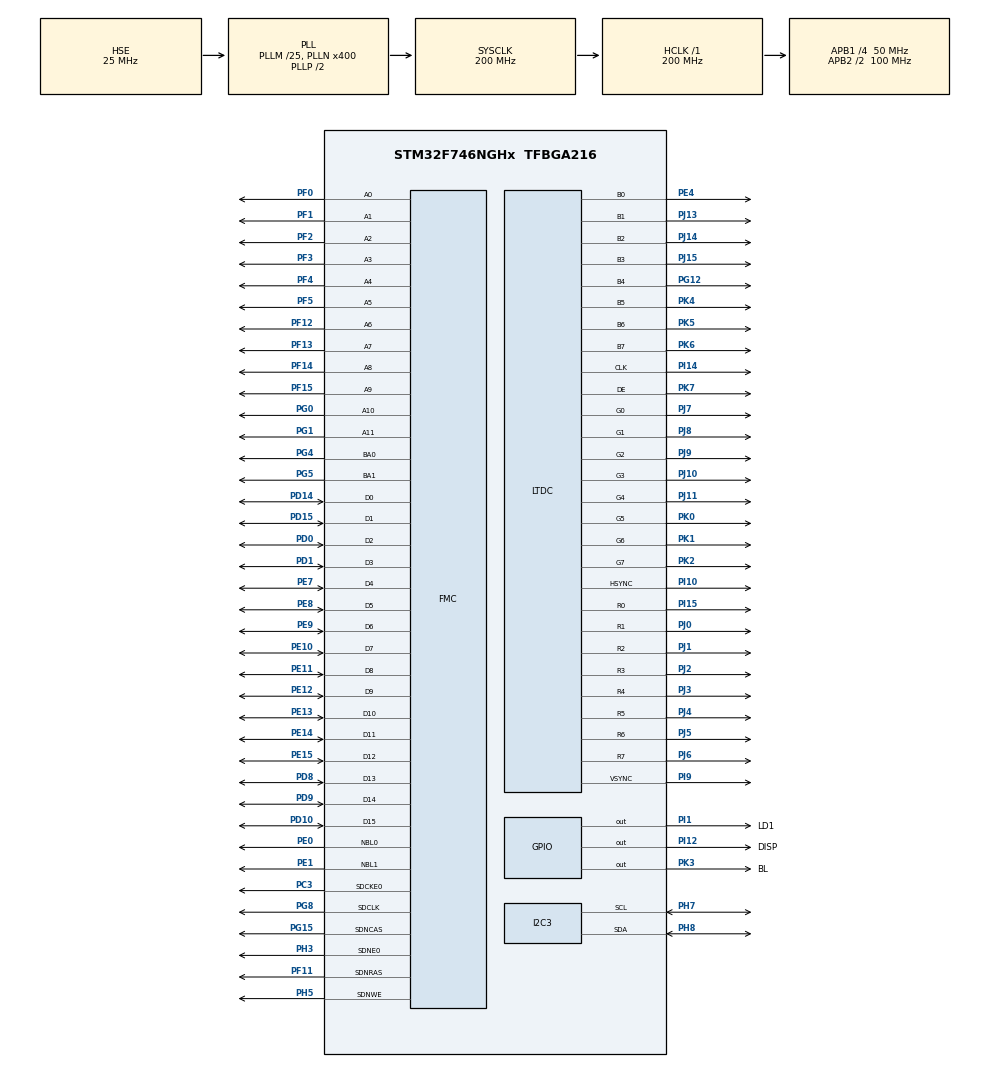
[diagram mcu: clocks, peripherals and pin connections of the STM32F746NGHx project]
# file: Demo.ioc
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FMC.CASLatency1=FMC_SDRAM_CAS_LATENCY_3
FMC.ExitSelfRefreshDelay1=7
FMC.LoadToActiveDelay1=2
FMC.RCDDelay1=2
FMC.RPDelay1=2
FMC.ReadBurst1=FMC_SDRAM_RBURST_ENABLE
FMC.RowCycleDelay1=7
FMC.SDClockPeriod1=FMC_SDRAM_CLOCK_PERIOD_2
FMC.SelfRefreshTime1=4
FMC.WriteRecoveryTime1=3
I2C3.Timing=0x00C0EAFF
LTDC.ActiveH=272
LTDC.ActiveW=480
LTDC.Alpha_L0=255
LTDC.BlendingFactor1_L0=LTDC_BLENDING_FACTOR1_PAxCA
LTDC.BlendingFactor2_L0=LTDC_BLENDING_FACTOR2_PAxCA
LTDC.FBStartAdress_L0=0xC0000000
LTDC.HBP=RK043FN48H_HBP
LTDC.HFP=RK043FN48H_HFP
LTDC.HSync=RK043FN48H_HSYNC
LTDC.ImageHeight_L0=272
LTDC.ImageWidth_L0=480
LTDC.Layers=0
LTDC.PixelFormat_L0=LTDC_PIXEL_FORMAT_RGB565
LTDC.VBP=RK043FN48H_VBP
LTDC.VFP=RK043FN48H_VFP
LTDC.VSync=RK043FN48H_VSYNC
LTDC.WindowX1_L0=480
LTDC.WindowY1_L0=272
Mcu.Family=STM32F7
Mcu.Name=STM32F746NGHx
Mcu.Package=TFBGA216
Mcu.UserConstants=RK043FN48H_HSYNC,41;RK043FN48H_VSYNC,10;RK043FN48H_HBP,13;RK043FN48H_VBP,2;RK043FN48H_WIDHT,480;RK043FN48H_HEIGHT,272;RK043FN48H_HFP,32;RK043FN48H_VFP,2
NVIC.DMA2D_IRQn=true\:5\:0\:true\:false\:true\:true\:true
NVIC.FMC_IRQn=true\:5\:0\:true\:false\:true\:true\:true
NVIC.LTDC_IRQn=true\:5\:0\:true\:false\:true\:true\:true
NVIC.PriorityGroup=NVIC_PRIORITYGROUP_4
NVIC.RCC_IRQn=true\:0\:0\:false\:false\:true\:true\:false
NVIC.TIM6_DAC_IRQn=true\:0\:0\:false\:false\:true\:false\:true
NVIC.TimeBase=TIM6_DAC_IRQn
NVIC.TimeBaseIP=TIM6
PA13.Mode=Serial_Wire
PA13.Signal=SYS_JTMS-SWDIO
PA14.Mode=Serial_Wire
PA14.Signal=SYS_JTCK-SWCLK
PC14/OSC32_IN.Mode=LSE-External-Oscillator
PC14/OSC32_IN.Signal=RCC_OSC32_IN
PC15/OSC32_OUT.Mode=LSE-External-Oscillator
PC15/OSC32_OUT.Signal=RCC_OSC32_OUT
PC3.Mode=SdramChipSelect1_1
PC3.Signal=FMC_SDCKE0
PD0.Signal=FMC_D2_DA2
PD1.Signal=FMC_D3_DA3
PD10.Signal=FMC_D15_DA15
PD14.Signal=FMC_D0_DA0
PD15.Signal=FMC_D1_DA1
PD8.Signal=FMC_D13_DA13
PD9.Signal=FMC_D14_DA14
PE0.Signal=FMC_NBL0
PE1.Signal=FMC_NBL1
PE10.Signal=FMC_D7_DA7
PE11.Signal=FMC_D8_DA8
PE12.Signal=FMC_D9_DA9
PE13.Signal=FMC_D10_DA10
PE14.Signal=FMC_D11_DA11
PE15.Signal=FMC_D12_DA12
PE4.Mode=RGB888
PE4.Signal=LTDC_B0
PE7.Signal=FMC_D4_DA4
PE8.Signal=FMC_D5_DA5
PE9.Signal=FMC_D6_DA6
PF0.Signal=FMC_A0
PF1.Signal=FMC_A1
PF11.Signal=FMC_SDNRAS
PF12.Signal=FMC_A6
PF13.Signal=FMC_A7
PF14.Signal=FMC_A8
PF15.Signal=FMC_A9
PF2.Signal=FMC_A2
PF3.Signal=FMC_A3
PF4.Signal=FMC_A4
PF5.Signal=FMC_A5
PG0.Signal=FMC_A10
PG1.Signal=FMC_A11
PG12.Mode=RGB888
PG12.Signal=LTDC_B4
PG15.Signal=FMC_SDNCAS
PG4.Signal=FMC_A14_BA0
PG5.Signal=FMC_A15_BA1
PG8.Signal=FMC_SDCLK
PH0/OSC_IN.Mode=HSE-External-Clock-Source
PH0/OSC_IN.Signal=RCC_OSC_IN
PH1/OSC_OUT.Mode=HSE-External-Clock-Source
PH1/OSC_OUT.Signal=RCC_OSC_OUT
PH3.Mode=SdramChipSelect1_1
PH3.Signal=FMC_SDNE0
PH5.Signal=FMC_SDNWE
PH7.Mode=I2C
PH7.Signal=I2C3_SCL
PH8.Mode=I2C
PH8.Signal=I2C3_SDA
PI1.GPIO_Label=LD1
PI1.Signal=GPIO_Output
PI10.Mode=RGB888
PI10.Signal=LTDC_HSYNC
PI12.GPIO_Label=DISP
PI12.PinState=GPIO_PIN_SET
PI12.Signal=GPIO_Output
PI14.Mode=RGB888
PI14.Signal=LTDC_CLK
PI15.Mode=RGB888
PI15.Signal=LTDC_R0
PI9.Mode=RGB888
PI9.Signal=LTDC_VSYNC
PJ0.Mode=RGB888
PJ0.Signal=LTDC_R1
PJ1.Mode=RGB888
PJ1.Signal=LTDC_R2
PJ10.Mode=RGB888
PJ10.Signal=LTDC_G3
PJ11.Mode=RGB888
PJ11.Signal=LTDC_G4
PJ13.Mode=RGB888
PJ13.Signal=LTDC_B1
PJ14.Mode=RGB888
PJ14.Signal=LTDC_B2
PJ15.Mode=RGB888
PJ15.Signal=LTDC_B3
PJ2.Mode=RGB888
PJ2.Signal=LTDC_R3
PJ3.Mode=RGB888
PJ3.Signal=LTDC_R4
PJ4.Mode=RGB888
PJ4.Signal=LTDC_R5
PJ5.Mode=RGB888
PJ5.Signal=LTDC_R6
PJ6.Mode=RGB888
PJ6.Signal=LTDC_R7
PJ7.Mode=RGB888
PJ7.Signal=LTDC_G0
PJ8.Mode=RGB888
PJ8.Signal=LTDC_G1
PJ9.Mode=RGB888
PJ9.Signal=LTDC_G2
PK0.Mode=RGB888
PK0.Signal=LTDC_G5
PK1.Mode=RGB888
PK1.Signal=LTDC_G6
PK2.Mode=RGB888
PK2.Signal=LTDC_G7
PK3.GPIO_Label=BL
PK3.PinState=GPIO_PIN_SET
PK3.Signal=GPIO_Output
PK4.Mode=RGB888
PK4.Signal=LTDC_B5
PK5.Mode=RGB888
PK5.Signal=LTDC_B6
PK6.Mode=RGB888
PK6.Signal=LTDC_B7
PK7.Mode=RGB888
PK7.Signal=LTDC_DE
ProjectManager.HeapSize=0x200
ProjectManager.StackSize=0x400
ProjectManager.TargetToolchain=MDK-ARM V5.27
RCC.AHBFreq_Value=200000000
RCC.APB1CLKDivider=RCC_HCLK_DIV4
RCC.APB1Freq_Value=50000000
RCC.APB1TimFreq_Value=100000000
RCC.APB2CLKDivider=RCC_HCLK_DIV2
RCC.APB2Freq_Value=100000000
RCC.APB2TimFreq_Value=200000000
RCC.CortexFreq_Value=200000000
RCC.HCLKFreq_Value=200000000
RCC.HSE_VALUE=25000000
RCC.HSI_VALUE=16000000
RCC.PLLM=25
RCC.PLLN=400
RCC.PLLSAIN=384
RCC.PLLSAIR=5
RCC.PLLSAIRDiv=RCC_PLLSAIDIVR_8
RCC.PLLSourceVirtual=RCC_PLLSOURCE_HSE
RCC.SYSCLKFreq_VALUE=200000000
RCC.SYSCLKSource=RCC_SYSCLKSOURCE_PLLCLK
RCC.USBFreq_Value=200000000
RCC.VCOOutputFreq_Value=400000000
SH.FMC_A0.0=FMC_A0,12b-sda1
SH.FMC_A1.0=FMC_A1,12b-sda1
SH.FMC_A10.0=FMC_A10,12b-sda1
SH.FMC_A11.0=FMC_A11,12b-sda1
SH.FMC_A14_BA0.0=FMC_BA0,FourSdramBanks1
SH.FMC_A15_BA1.0=FMC_BA1,FourSdramBanks1
SH.FMC_A2.0=FMC_A2,12b-sda1
SH.FMC_A3.0=FMC_A3,12b-sda1
SH.FMC_A4.0=FMC_A4,12b-sda1
SH.FMC_A5.0=FMC_A5,12b-sda1
SH.FMC_A6.0=FMC_A6,12b-sda1
SH.FMC_A7.0=FMC_A7,12b-sda1
SH.FMC_A8.0=FMC_A8,12b-sda1
SH.FMC_A9.0=FMC_A9,12b-sda1
SH.FMC_D0_DA0.0=FMC_D0,sd-16b-d1
SH.FMC_D10_DA10.0=FMC_D10,sd-16b-d1
SH.FMC_D11_DA11.0=FMC_D11,sd-16b-d1
SH.FMC_D12_DA12.0=FMC_D12,sd-16b-d1
SH.FMC_D13_DA13.0=FMC_D13,sd-16b-d1
SH.FMC_D14_DA14.0=FMC_D14,sd-16b-d1
SH.FMC_D15_DA15.0=FMC_D15,sd-16b-d1
SH.FMC_D1_DA1.0=FMC_D1,sd-16b-d1
SH.FMC_D2_DA2.0=FMC_D2,sd-16b-d1
SH.FMC_D3_DA3.0=FMC_D3,sd-16b-d1
SH.FMC_D4_DA4.0=FMC_D4,sd-16b-d1
SH.FMC_D5_DA5.0=FMC_D5,sd-16b-d1
SH.FMC_D6_DA6.0=FMC_D6,sd-16b-d1
SH.FMC_D7_DA7.0=FMC_D7,sd-16b-d1
SH.FMC_D8_DA8.0=FMC_D8,sd-16b-d1
SH.FMC_D9_DA9.0=FMC_D9,sd-16b-d1
SH.FMC_NBL0.0=FMC_NBL0,Sd2ByteEnable1
SH.FMC_NBL1.0=FMC_NBL1,Sd2ByteEnable1
SH.FMC_SDCLK.0=FMC_SDCLK,12b-sda1
SH.FMC_SDNCAS.0=FMC_SDNCAS,12b-sda1
SH.FMC_SDNRAS.0=FMC_SDNRAS,12b-sda1
SH.FMC_SDNWE.0=FMC_SDNWE,12b-sda1
STMicroelectronics.X-CUBE-TOUCHGFX.4.13.0.ApplicationCcGraphicsJjApplication=TouchGFXOoGenerator
STMicroelectronics.X-CUBE-TOUCHGFX.4.13.0.tgfx_address1=0xC0000000
STMicroelectronics.X-CUBE-TOUCHGFX.4.13.0.tgfx_address2=0xC003fc00
STMicroelectronics.X-CUBE-TOUCHGFX.4.13.0.tgfx_buffering_strategy=Double
STMicroelectronics.X-CUBE-TOUCHGFX.4.13.0.tgfx_display_interface=disp_ltdc
STMicroelectronics.X-CUBE-TOUCHGFX.4.13.0.tgfx_hardware_accelerator=dma_2d
STMicroelectronics.X-CUBE-TOUCHGFX.4.13.0.tgfx_location=By Address
STMicroelectronics.X-CUBE-TOUCHGFX.4.13.0.tgfx_oswrapper=Custom
STMicroelectronics.X-CUBE-TOUCHGFX.4.13.0.tgfx_pixel_format=RGB565\:16
STMicroelectronics.X-CUBE-TOUCHGFX.4.13.0.tgfx_vsync=vsync_ltdc
VP_CRC_VS_CRC.Mode=CRC_Activate
VP_DMA2D_VS_DMA2D.Mode=DMA2D_Activate
VP_STMicroelectronics.X-CUBE-TOUCHGFX_VS_GraphicsJjApplication_4.13.0.Mode=GraphicsJjApplication
VP_SYS_VS_tim6.Mode=TIM6
board=custom

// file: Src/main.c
/* USER CODE BEGIN Header */
/**
  ******************************************************************************
  * @file           : main.c
  * @brief          : Main program body
  ******************************************************************************
  * @attention
  *
  * <h2><center>&copy; Copyright (c) 2020 STMicroelectronics.
  * All rights reserved.</center></h2>
  *
  * This software component is licensed by ST under Ultimate Liberty license
  * SLA0044, the "License"; You may not use this file except in compliance with
  * the License. You may obtain a copy of the License at:
  *                             www.st.com/SLA0044
  *
  ******************************************************************************
  */
/* USER CODE END Header */

#include "main.h"
#include "app_touchgfx.h"

/* USER CODE BEGIN Includes */
#include <rtthread.h>
/* USER CODE END Includes */

/* USER CODE BEGIN PD */
#define SDRAM_MODEREG_BURST_LENGTH_1             ((uint16_t)0x0000)
#define SDRAM_MODEREG_BURST_LENGTH_2             ((uint16_t)0x0001)
#define SDRAM_MODEREG_BURST_LENGTH_4             ((uint16_t)0x0002)
#define SDRAM_MODEREG_BURST_LENGTH_8             ((uint16_t)0x0004)
#define SDRAM_MODEREG_BURST_TYPE_SEQUENTIAL      ((uint16_t)0x0000)
#define SDRAM_MODEREG_BURST_TYPE_INTERLEAVED     ((uint16_t)0x0008)
#define SDRAM_MODEREG_CAS_LATENCY_2              ((uint16_t)0x0020)
#define SDRAM_MODEREG_CAS_LATENCY_3              ((uint16_t)0x0030)
#define SDRAM_MODEREG_OPERATING_MODE_STANDARD    ((uint16_t)0x0000)
#define SDRAM_MODEREG_WRITEBURST_MODE_PROGRAMMED ((uint16_t)0x0000)
#define SDRAM_MODEREG_WRITEBURST_MODE_SINGLE     ((uint16_t)0x0200)
/* USER CODE END PD */

CRC_HandleTypeDef hcrc;

DMA2D_HandleTypeDef hdma2d;

I2C_HandleTypeDef hi2c3;

LTDC_HandleTypeDef hltdc;

SDRAM_HandleTypeDef hsdram1;

void SystemClock_Config(void);
static void MX_GPIO_Init(void);
static void MX_CRC_Init(void);
static void MX_DMA2D_Init(void);
static void MX_FMC_Init(void);
static void MX_LTDC_Init(void);
static void MX_I2C3_Init(void);
/* USER CODE BEGIN PFP */
static void MX_SDRAM_Init(void);
/* USER CODE END PFP */

/* USER CODE BEGIN 0 */
static rt_thread_t tid = RT_NULL;
static void TouchGFX_entry(void *param)
{
    MX_TouchGFX_Process();
    for(;;)
    {
        rt_thread_delay(10);
    }
}
/* USER CODE END 0 */

int main(void)
{

    /* MCU Configuration--------------------------------------------------------*/

    /* Reset of all peripherals, Initializes the Flash interface and the Systick. */
    //HAL_Init();

    /* Configure the system clock */
    //SystemClock_Config();

    /* Initialize all configured peripherals */
    MX_GPIO_Init();
    MX_CRC_Init();
    MX_DMA2D_Init();
    MX_FMC_Init();
    MX_LTDC_Init();
    MX_I2C3_Init();
    MX_TouchGFX_Init();
    /* USER CODE BEGIN 2 */
    tid = rt_thread_create("TouchGFX", TouchGFX_entry, RT_NULL, 1024, 15, 20);
    if(tid != RT_NULL)
        rt_thread_startup(tid);
    /* USER CODE END 2 */

    /* Infinite loop */
    while (1)
    {

        //MX_TouchGFX_Process();
        /* USER CODE BEGIN 3 */
        HAL_GPIO_WritePin(LD1_GPIO_Port, LD1_Pin, GPIO_PIN_SET);
        rt_thread_delay(500);
        HAL_GPIO_WritePin(LD1_GPIO_Port, LD1_Pin, GPIO_PIN_RESET);
        rt_thread_delay(500);
    }
    /* USER CODE END 3 */
}

void SystemClock_Config(void)
{
    RCC_OscInitTypeDef RCC_OscInitStruct = {0};
    RCC_ClkInitTypeDef RCC_ClkInitStruct = {0};
    RCC_PeriphCLKInitTypeDef PeriphClkInitStruct = {0};

    /** Configure LSE Drive Capability
    */
    HAL_PWR_EnableBkUpAccess();
    /** Configure the main internal regulator output voltage
    */
    __HAL_RCC_PWR_CLK_ENABLE();
    __HAL_PWR_VOLTAGESCALING_CONFIG(PWR_REGULATOR_VOLTAGE_SCALE1);
    /** Initializes the CPU, AHB and APB busses clocks
    */
    RCC_OscInitStruct.OscillatorType = RCC_OSCILLATORTYPE_HSE;
    RCC_OscInitStruct.HSEState = RCC_HSE_BYPASS;
    RCC_OscInitStruct.PLL.PLLState = RCC_PLL_ON;
    RCC_OscInitStruct.PLL.PLLSource = RCC_PLLSOURCE_HSE;
    RCC_OscInitStruct.PLL.PLLM = 25;
    RCC_OscInitStruct.PLL.PLLN = 400;
    RCC_OscInitStruct.PLL.PLLP = RCC_PLLP_DIV2;
    RCC_OscInitStruct.PLL.PLLQ = 2;
    if (HAL_RCC_OscConfig(&RCC_OscInitStruct) != HAL_OK)
    {
        Error_Handler();
    }
    /** Activate the Over-Drive mode
    */
    if (HAL_PWREx_EnableOverDrive() != HAL_OK)
    {
        Error_Handler();
    }
    /** Initializes the CPU, AHB and APB busses clocks
    */
    RCC_ClkInitStruct.ClockType = RCC_CLOCKTYPE_HCLK | RCC_CLOCKTYPE_SYSCLK
                                  | RCC_CLOCKTYPE_PCLK1 | RCC_CLOCKTYPE_PCLK2;
    RCC_ClkInitStruct.SYSCLKSource = RCC_SYSCLKSOURCE_PLLCLK;
    RCC_ClkInitStruct.AHBCLKDivider = RCC_SYSCLK_DIV1;
    RCC_ClkInitStruct.APB1CLKDivider = RCC_HCLK_DIV4;
    RCC_ClkInitStruct.APB2CLKDivider = RCC_HCLK_DIV2;

    if (HAL_RCC_ClockConfig(&RCC_ClkInitStruct, FLASH_LATENCY_6) != HAL_OK)
    {
        Error_Handler();
    }
    PeriphClkInitStruct.PeriphClockSelection = RCC_PERIPHCLK_LTDC | RCC_PERIPHCLK_I2C3;
    PeriphClkInitStruct.PLLSAI.PLLSAIN = 384;
    PeriphClkInitStruct.PLLSAI.PLLSAIR = 5;
    PeriphClkInitStruct.PLLSAI.PLLSAIQ = 2;
    PeriphClkInitStruct.PLLSAI.PLLSAIP = RCC_PLLSAIP_DIV2;
    PeriphClkInitStruct.PLLSAIDivQ = 1;
    PeriphClkInitStruct.PLLSAIDivR = RCC_PLLSAIDIVR_8;
    PeriphClkInitStruct.I2c3ClockSelection = RCC_I2C3CLKSOURCE_PCLK1;
    if (HAL_RCCEx_PeriphCLKConfig(&PeriphClkInitStruct) != HAL_OK)
    {
        Error_Handler();
    }
}

static void MX_CRC_Init(void)
{

    hcrc.Instance = CRC;
    hcrc.Init.DefaultPolynomialUse = DEFAULT_POLYNOMIAL_ENABLE;
    hcrc.Init.DefaultInitValueUse = DEFAULT_INIT_VALUE_ENABLE;
    hcrc.Init.InputDataInversionMode = CRC_INPUTDATA_INVERSION_NONE;
    hcrc.Init.OutputDataInversionMode = CRC_OUTPUTDATA_INVERSION_DISABLE;
    hcrc.InputDataFormat = CRC_INPUTDATA_FORMAT_BYTES;
    if (HAL_CRC_Init(&hcrc) != HAL_OK)
    {
        Error_Handler();
    }

}

static void MX_DMA2D_Init(void)
{

    hdma2d.Instance = DMA2D;
    hdma2d.Init.Mode = DMA2D_M2M;
    hdma2d.Init.ColorMode = DMA2D_OUTPUT_ARGB8888;
    hdma2d.Init.OutputOffset = 0;
    hdma2d.LayerCfg[1].InputOffset = 0;
    hdma2d.LayerCfg[1].InputColorMode = DMA2D_INPUT_ARGB8888;
    hdma2d.LayerCfg[1].AlphaMode = DMA2D_NO_MODIF_ALPHA;
    hdma2d.LayerCfg[1].InputAlpha = 0;
    if (HAL_DMA2D_Init(&hdma2d) != HAL_OK)
    {
        Error_Handler();
    }
    if (HAL_DMA2D_ConfigLayer(&hdma2d, 1) != HAL_OK)
    {
        Error_Handler();
    }

}

static void MX_I2C3_Init(void)
{

    hi2c3.Instance = I2C3;
    hi2c3.Init.Timing = 0x00C0EAFF;
    hi2c3.Init.OwnAddress1 = 0;
    hi2c3.Init.AddressingMode = I2C_ADDRESSINGMODE_7BIT;
    hi2c3.Init.DualAddressMode = I2C_DUALADDRESS_DISABLE;
    hi2c3.Init.OwnAddress2 = 0;
    hi2c3.Init.OwnAddress2Masks = I2C_OA2_NOMASK;
    hi2c3.Init.GeneralCallMode = I2C_GENERALCALL_DISABLE;
    hi2c3.Init.NoStretchMode = I2C_NOSTRETCH_DISABLE;
    if (HAL_I2C_Init(&hi2c3) != HAL_OK)
    {
        Error_Handler();
    }
    /** Configure Analogue filter
    */
    if (HAL_I2CEx_ConfigAnalogFilter(&hi2c3, I2C_ANALOGFILTER_ENABLE) != HAL_OK)
    {
        Error_Handler();
    }
    /** Configure Digital filter
    */
    if (HAL_I2CEx_ConfigDigitalFilter(&hi2c3, 0) != HAL_OK)
    {
        Error_Handler();
    }

}

static void MX_LTDC_Init(void)
{

    LTDC_LayerCfgTypeDef pLayerCfg = {0};

    hltdc.Instance = LTDC;
    hltdc.Init.HSPolarity = LTDC_HSPOLARITY_AL;
    hltdc.Init.VSPolarity = LTDC_VSPOLARITY_AL;
    hltdc.Init.DEPolarity = LTDC_DEPOLARITY_AL;
    hltdc.Init.PCPolarity = LTDC_PCPOLARITY_IPC;
    hltdc.Init.HorizontalSync = 40;
    hltdc.Init.VerticalSync = 9;
    hltdc.Init.AccumulatedHBP = 53;
    hltdc.Init.AccumulatedVBP = 11;
    hltdc.Init.AccumulatedActiveW = 533;
    hltdc.Init.AccumulatedActiveH = 283;
    hltdc.Init.TotalWidth = 565;
    hltdc.Init.TotalHeigh = 285;
    hltdc.Init.Backcolor.Blue = 0;
    hltdc.Init.Backcolor.Green = 0;
    hltdc.Init.Backcolor.Red = 0;
    if (HAL_LTDC_Init(&hltdc) != HAL_OK)
    {
        Error_Handler();
    }
    pLayerCfg.WindowX0 = 0;
    pLayerCfg.WindowX1 = 480;
    pLayerCfg.WindowY0 = 0;
    pLayerCfg.WindowY1 = 272;
    pLayerCfg.PixelFormat = LTDC_PIXEL_FORMAT_RGB565;
    pLayerCfg.Alpha = 255;
    pLayerCfg.Alpha0 = 0;
    pLayerCfg.BlendingFactor1 = LTDC_BLENDING_FACTOR1_PAxCA;
    pLayerCfg.BlendingFactor2 = LTDC_BLENDING_FACTOR2_PAxCA;
    pLayerCfg.FBStartAdress = 0xC0000000;
    pLayerCfg.ImageWidth = 480;
    pLayerCfg.ImageHeight = 272;
    pLayerCfg.Backcolor.Blue = 0;
    pLayerCfg.Backcolor.Green = 0;
    pLayerCfg.Backcolor.Red = 0;
    if (HAL_LTDC_ConfigLayer(&hltdc, &pLayerCfg, 0) != HAL_OK)
    {
        Error_Handler();
    }

}

/* FMC initialization function */
static void MX_FMC_Init(void)
{

    FMC_SDRAM_TimingTypeDef SdramTiming = {0};

    /** Perform the SDRAM1 memory initialization sequence
    */
    hsdram1.Instance = FMC_SDRAM_DEVICE;
    /* hsdram1.Init */
    hsdram1.Init.SDBank = FMC_SDRAM_BANK1;
    hsdram1.Init.ColumnBitsNumber = FMC_SDRAM_COLUMN_BITS_NUM_8;
    hsdram1.Init.RowBitsNumber = FMC_SDRAM_ROW_BITS_NUM_12;
    hsdram1.Init.MemoryDataWidth = FMC_SDRAM_MEM_BUS_WIDTH_16;
    hsdram1.Init.InternalBankNumber = FMC_SDRAM_INTERN_BANKS_NUM_4;
    hsdram1.Init.CASLatency = FMC_SDRAM_CAS_LATENCY_3;
    hsdram1.Init.WriteProtection = FMC_SDRAM_WRITE_PROTECTION_DISABLE;
    hsdram1.Init.SDClockPeriod = FMC_SDRAM_CLOCK_PERIOD_2;
    hsdram1.Init.ReadBurst = FMC_SDRAM_RBURST_ENABLE;
    hsdram1.Init.ReadPipeDelay = FMC_SDRAM_RPIPE_DELAY_0;
    /* SdramTiming */
    SdramTiming.LoadToActiveDelay = 2;
    SdramTiming.ExitSelfRefreshDelay = 7;
    SdramTiming.SelfRefreshTime = 4;
    SdramTiming.RowCycleDelay = 7;
    SdramTiming.WriteRecoveryTime = 3;
    SdramTiming.RPDelay = 2;
    SdramTiming.RCDDelay = 2;

    if (HAL_SDRAM_Init(&hsdram1, &SdramTiming) != HAL_OK)
    {
        Error_Handler( );
    }

    /* USER CODE BEGIN FMC_Init 2 */
    MX_SDRAM_Init();
    /* USER CODE END FMC_Init 2 */
}

static void MX_GPIO_Init(void)
{
    GPIO_InitTypeDef GPIO_InitStruct = {0};

    /* GPIO Ports Clock Enable */
    __HAL_RCC_GPIOE_CLK_ENABLE();
    __HAL_RCC_GPIOA_CLK_ENABLE();
    __HAL_RCC_GPIOG_CLK_ENABLE();
    __HAL_RCC_GPIOJ_CLK_ENABLE();
    __HAL_RCC_GPIOD_CLK_ENABLE();
    __HAL_RCC_GPIOK_CLK_ENABLE();
    __HAL_RCC_GPIOF_CLK_ENABLE();
    __HAL_RCC_GPIOI_CLK_ENABLE();
    __HAL_RCC_GPIOC_CLK_ENABLE();
    __HAL_RCC_GPIOH_CLK_ENABLE();

    /*Configure GPIO pin Output Level */
    HAL_GPIO_WritePin(BL_GPIO_Port, BL_Pin, GPIO_PIN_SET);

    /*Configure GPIO pin Output Level */
    HAL_GPIO_WritePin(LD1_GPIO_Port, LD1_Pin, GPIO_PIN_RESET);

    /*Configure GPIO pin Output Level */
    HAL_GPIO_WritePin(DISP_GPIO_Port, DISP_Pin, GPIO_PIN_SET);

    /*Configure GPIO pin : BL_Pin */
    GPIO_InitStruct.Pin = BL_Pin;
    GPIO_InitStruct.Mode = GPIO_MODE_OUTPUT_PP;
    GPIO_InitStruct.Pull = GPIO_NOPULL;
    GPIO_InitStruct.Speed = GPIO_SPEED_FREQ_LOW;
    HAL_GPIO_Init(BL_GPIO_Port, &GPIO_InitStruct);

    /*Configure GPIO pins : LD1_Pin DISP_Pin */
    GPIO_InitStruct.Pin = LD1_Pin | DISP_Pin;
    GPIO_InitStruct.Mode = GPIO_MODE_OUTPUT_PP;
    GPIO_InitStruct.Pull = GPIO_NOPULL;
    GPIO_InitStruct.Speed = GPIO_SPEED_FREQ_LOW;
    HAL_GPIO_Init(GPIOI, &GPIO_InitStruct);

}

/* USER CODE BEGIN 4 */

/**
  * @brief SDRAM Initialization Function
  * @param None
  * @retval None
  */
static void MX_SDRAM_Init(void)
{
    __IO uint32_t tmpmrd = 0;

    FMC_SDRAM_CommandTypeDef Command;

    /* Step 1: Config clock */
    Command.CommandMode             = FMC_SDRAM_CMD_CLK_ENABLE;
    Command.CommandTarget           = FMC_SDRAM_CMD_TARGET_BANK1;
    Command.AutoRefreshNumber       = 1;
    Command.ModeRegisterDefinition  = 0;
    HAL_SDRAM_SendCommand(&hsdram1, &Command, 0xFFFF);

    /* Step 2: Insert Delay */
    HAL_Delay(1);

    /* Step 3: Config pall */
    Command.CommandMode             = FMC_SDRAM_CMD_PALL;
    Command.CommandTarget           = FMC_SDRAM_CMD_TARGET_BANK1;
    Command.AutoRefreshNumber       = 1;
    Command.ModeRegisterDefinition  = 0;
    HAL_SDRAM_SendCommand(&hsdram1, &Command, 0xFFFF);

    /* Step 3: Config auto refresh */
    Command.CommandMode             = FMC_SDRAM_CMD_AUTOREFRESH_MODE;
    Command.CommandTarget           = FMC_SDRAM_CMD_TARGET_BANK1;
    Command.AutoRefreshNumber       = 8;
    Command.ModeRegisterDefinition  = 0;
    HAL_SDRAM_SendCommand(&hsdram1, &Command, 0xFFFF);

    /* Step 4: Config memory mode */
    tmpmrd = (uint32_t)SDRAM_MODEREG_BURST_LENGTH_1   | //设置突发长度:1(可以是1/2/4/8)
             SDRAM_MODEREG_BURST_TYPE_SEQUENTIAL      | //设置突发类型:连续(可以是连续/交错)
             SDRAM_MODEREG_CAS_LATENCY_3              | //设置CAS值:3(可以是2/3)
             SDRAM_MODEREG_OPERATING_MODE_STANDARD    | //设置操作模式:0,标准模式
             SDRAM_MODEREG_WRITEBURST_MODE_SINGLE;      //设置突发写模式:1,单点访问
    Command.CommandMode             = FMC_SDRAM_CMD_LOAD_MODE;
    Command.CommandTarget           = FMC_SDRAM_CMD_TARGET_BANK1;
    Command.AutoRefreshNumber       = 1;
    Command.ModeRegisterDefinition  = tmpmrd;
    HAL_SDRAM_SendCommand(&hsdram1, &Command, 0xFFFF);

    /* Step 5: Set refresh rate */
    HAL_SDRAM_ProgramRefreshRate(&hsdram1, 1800);
}

/* USER CODE END 4 */

void HAL_TIM_PeriodElapsedCallback(TIM_HandleTypeDef *htim)
{
    if (htim->Instance == TIM6)
    {
        HAL_IncTick();
    }
}

void Error_Handler(void)
{
}

/************************ (C) COPYRIGHT STMicroelectronics *****END OF FILE****/
